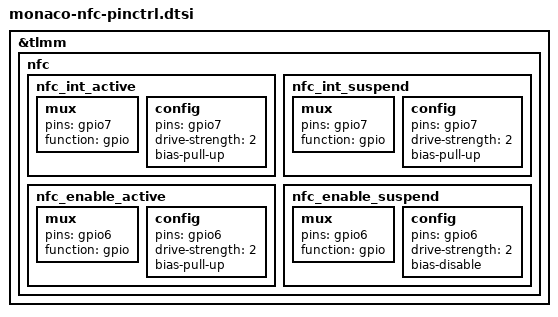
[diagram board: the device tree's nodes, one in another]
&tlmm {
	nfc {
			nfc_int_active: nfc_int_active {
				/* active state */
				mux {
					/* NFC Read Interrupt */
					pins = "gpio7";
					function = "gpio";
				};

				config {
					pins = "gpio7";
					drive-strength = <2>; /* 2 MA */
					bias-pull-up;
				};
			};

			nfc_int_suspend: nfc_int_suspend {
				/* sleep state */
				mux {
					/* NFC Read Interrupt */
					pins = "gpio7";
					function = "gpio";
				};

				config {
					pins = "gpio7";
					drive-strength = <2>; /* 2 MA */
					bias-pull-up;
				};
			};

			nfc_enable_active: nfc_enable_active {
				/* active state */
				mux {
					/* Enable */
					pins = "gpio6";
					function = "gpio";
				};

				config {
					pins = "gpio6";
					drive-strength = <2>; /* 2 MA */
					bias-pull-up;
				};
			};

			nfc_enable_suspend: nfc_enable_suspend {
				/* sleep state */
				mux {
					/* Enable */
					pins = "gpio6";
					function = "gpio";
				};

				config {
					pins = "gpio6";
					drive-strength = <2>; /* 2 MA */
					bias-disable;
				};
			};
	}; //nfc
}; //tlmm
